# CC1311P3 register map
File version: 1.0
CPU: CM4 1.0, other endian, MPU, FPU, 3 interrupt priority bits
Registers are 32-bit, read-write, reset 0x0 unless marked. A register's access mark holds for its fields unless they carry their own. Offsets are from the block's base; [hi:lo] are bit positions; {n}, {i} and the like mark numbered series; 'fields as' and 'values as' point back to an identical list.

## AON_IOC — Always On (AON) IO Controller - controls IO operation when the MCU IO Controller (IOC) is powered off and resides in the AON domain. Note: This module only supports 32 bit Read/Write access from MCU.
Base 0x40094000
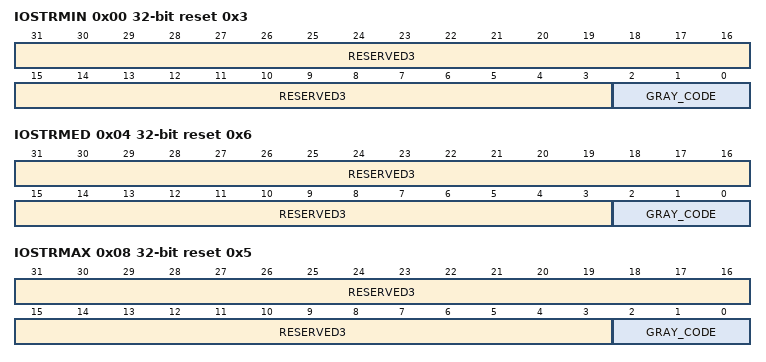
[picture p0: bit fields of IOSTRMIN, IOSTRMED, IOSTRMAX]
0x00 IOSTRMIN reset 0x3 — Internal. Only to be used through TI provided API.
  [31:3] RESERVED3 ro — [31:3] Internal. Only to be used through TI provided API.
  [2:0] GRAY_CODE — [2:0] Internal. Only to be used through TI provided API.
0x04 IOSTRMED reset 0x6 — Internal. Only to be used through TI provided API.
  fields as IOSTRMIN
0x08 IOSTRMAX reset 0x5 — Internal. Only to be used through TI provided API.
  fields as IOSTRMIN
0x10 CLK32KCTL reset 0x1 — SCLK_LF External Output Control
  [0] OE_N — [0:0] 0: Output enable active. SCLK_LF output on IO pin that has PORT_ID (for example IOC:IOCFG0.PORT_ID) set to AON_CLK32K. 1: Output enable not active
0x14 TCKCTL reset 0x1 — TCK IO Pin Control
  [0] EN — [0:0] 0: Input driver for TCK disabled. 1: Input driver for TCK enabled.

## AUX_SMPH — AUX Semaphore (AUX_SMPH) provides hardware means to share modules in AUX safely between CPUs based on resource ownership. AUX_SMPH operates at AUX bus rate.
Base 0x400C8000
{0x0+4i} SMPH{i} reset 0x1 (i=0..7) — Semaphore {i}
  [0] STAT — [0:0] Request or release of semaphore. Request by read: 0: Semaphore not available. 1: Semaphore granted. Release by write: 0: Do not use. 1: Release semaphore.
0x20 AUTOTAKE — Auto Take Sticky Request for Single Semaphore.
  [2:0] SMPH_ID — [2:0] Write the semaphore ID,0x0-0x7, to SMPH_ID to request this semaphore until it is granted. When semaphore SMPH_ID is granted, event AUX_EVCTL:EVSTAT3.AUX_SMPH_AUTOTAKE_DONE becomes 1. The event becomes 0 when software releases the semaphore or writes a new value to SMPH_ID. To avoid corrupted semaphores: - Usage of this functionality must be restricted to one CPU core. - Software must wait until AUX_EVCTL:EVSTAT3.AUX_SMPH_AUTOTAKE_DONE is 1 before it writes a new value to SMPH_ID.

## CPU_FPB — Cortex-M's Flash Patch and Breakpoint (FPB)
Base 0xE0002000
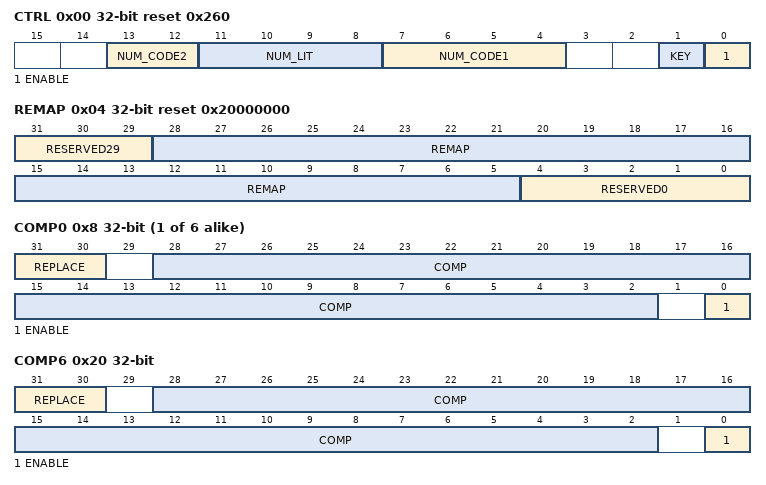
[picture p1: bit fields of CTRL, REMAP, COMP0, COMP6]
0x00 CTRL reset 0x260 — Control This register is used to enable the flash patch block.
  [13:12] NUM_CODE2 ro — [13:12] Number of full banks of code comparators, sixteen comparators per bank. Where less than sixteen code comparators are provided, the bank count is zero, and the number present indicated by NUM_CODE1. This read only field contains 3'b000 to indicate 0 banks for Cortex-M processor.
  [11:8] NUM_LIT ro — [11:8] Number of literal slots field. 0x0: No literal slots 0x2: Two literal slots
  [7:4] NUM_CODE1 ro — [7:4] Number of code slots field. 0x0: No code slots 0x2: Two code slots 0x6: Six code slots
  [1] KEY wo — [1:1] Key field. In order to write to this register, this bit-field must be written to '1'. This bit always reads 0.
  [0] ENABLE — [0:0] Flash patch unit enable bit 0x0: Flash patch unit disabled 0x1: Flash patch unit enabled
0x04 REMAP reset 0x20000000 — Remap This register provides the remap base address location where a matched addresses are remapped. The three most significant bits and the five least significant bits of the remap base address are hard-coded to 3'b001 and 5'b00000 respectively. The remap base address must be in system space and is it required to be 8-word aligned, with one word allocated to each of the eight FPB comparators.
  [31:29] RESERVED29 ro — [31:29] This field always reads 3'b001. Writing to this field is ignored.
  [28:5] REMAP — [28:5] Remap base address field.
  [4:0] RESERVED0 ro — [4:0] This field always reads 0. Writing to this field is ignored.
{0x8+4i} COMP{i} (i=0..5) — Comparator {i}
  [31:30] REPLACE — [31:30] This selects what happens when the COMP address is matched. Address remapping only takes place for the 0x0 setting. 0x0: Remap to remap address. See REMAP.REMAP 0x1: Set BKPT on lower halfword, upper is unaffected 0x2: Set BKPT on upper halfword, lower is unaffected 0x3: Set BKPT on both lower and upper halfwords.
  [28:2] COMP — [28:2] Comparison address.
  [0] ENABLE — [0:0] Compare and remap enable comparator {i}. CTRL.ENABLE must also be set to enable comparisons. 0x0: Compare and remap for comparator {i} disabled 0x1: Compare and remap for comparator {i} enabled
0x20 COMP6 — Comparator 6
  [31:30] REPLACE — [31:30] This selects what happens when the COMP address is matched. Comparator 6 is a literal comparator and the only supported setting is 0x0. Other settings will be ignored. 0x0: Remap to remap address. See REMAP.REMAP 0x1: Set BKPT on lower halfword, upper is unaffected 0x2: Set BKPT on upper halfword, lower is unaffected 0x3: Set BKPT on both lower and upper halfwords.
  [28:2] COMP — [28:2] Comparison address.
  [0] ENABLE — [0:0] Compare and remap enable comparator 6. CTRL.ENABLE must also be set to enable comparisons. 0x0: Compare and remap for comparator 6 disabled 0x1: Compare and remap for comparator 6 enabled
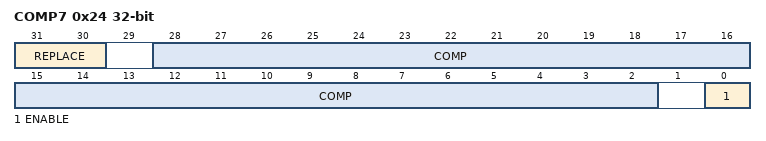
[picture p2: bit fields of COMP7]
0x24 COMP7 — Comparator 7
  [31:30] REPLACE — [31:30] This selects what happens when the COMP address is matched. Comparator 7 is a literal comparator and the only supported setting is 0x0. Other settings will be ignored. 0x0: Remap to remap address. See REMAP.REMAP 0x1: Set BKPT on lower halfword, upper is unaffected 0x2: Set BKPT on upper halfword, lower is unaffected 0x3: Set BKPT on both lower and upper halfwords.
  [28:2] COMP — [28:2] Comparison address.
  [0] ENABLE — [0:0] Compare and remap enable comparator 7. CTRL.ENABLE must also be set to enable comparisons. 0x0: Compare and remap for comparator 7 disabled 0x1: Compare and remap for comparator 7 enabled
